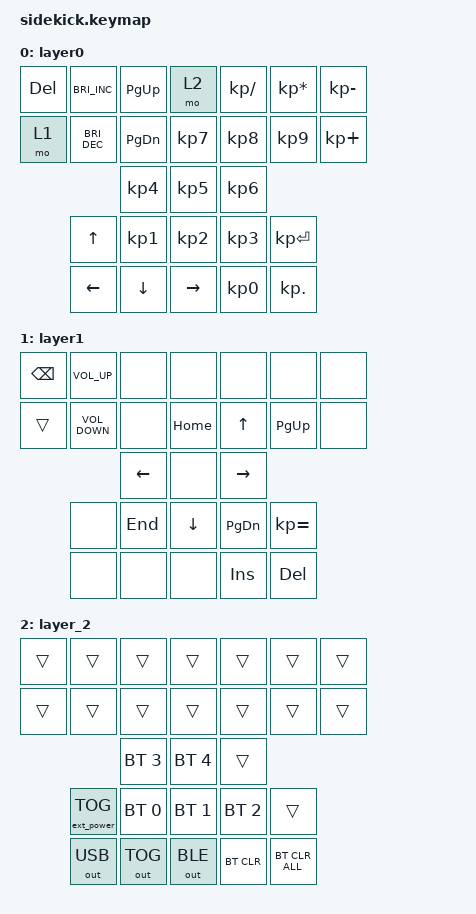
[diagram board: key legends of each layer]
#include <behaviors.dtsi>
#include <dt-bindings/zmk/bt.h>
#include <dt-bindings/zmk/ext_power.h>
#include <dt-bindings/zmk/keys.h>
#include <dt-bindings/zmk/outputs.h>

/ {
    keymap {
        compatible = "zmk,keymap";

        layer0 {
            bindings = <
&kp DELETE  &kp C_BRIGHTNESS_INC  &kp PAGE_UP  &mo 2  &kp KP_SLASH  &kp KP_ASTERISK  &kp KP_MINUS  
&mo 1  &kp C_BRIGHTNESS_DEC  &kp PAGE_DOWN  &kp KP_N7  &kp KP_N8  &kp KP_N9  &kp KP_PLUS  
&kp KP_N4  &kp KP_N5  &kp KP_N6  
&kp UP  &kp KP_N1  &kp KP_N2  &kp KP_N3  &kp KP_ENTER  
&kp LEFT  &kp DOWN  &kp RIGHT  &kp KP_N0  &kp KP_DOT
            >;
        };

        layer1 {
            bindings = <
&kp BACKSPACE  &kp C_VOLUME_UP  &none  &none  &none  &none  &none  &trans  &kp C_VOLUME_DOWN  &none  &kp HOME  &kp UP  &kp PAGE_UP  &none  &kp LEFT  &none  &kp RIGHT  &none  &kp END  &kp DOWN  &kp PAGE_DOWN  &kp KP_EQUAL  &none  &none  &none  &kp INSERT  &kp DELETE
            >;
        };

        layer_2 {
            bindings = <
&trans  &trans  &trans  &trans  &trans  &trans  &trans  &trans  &trans  &trans  &trans  &trans  &trans  &trans  &bt BT_SEL 3  &bt BT_SEL 4  &trans  &ext_power EP_TOG  &bt BT_SEL 0  &bt BT_SEL 1  &bt BT_SEL 2  &trans  &out OUT_USB  &out OUT_TOG  &out OUT_BLE  &bt BT_CLR  &bt BT_CLR_ALL
            >;
        };
    };
};
